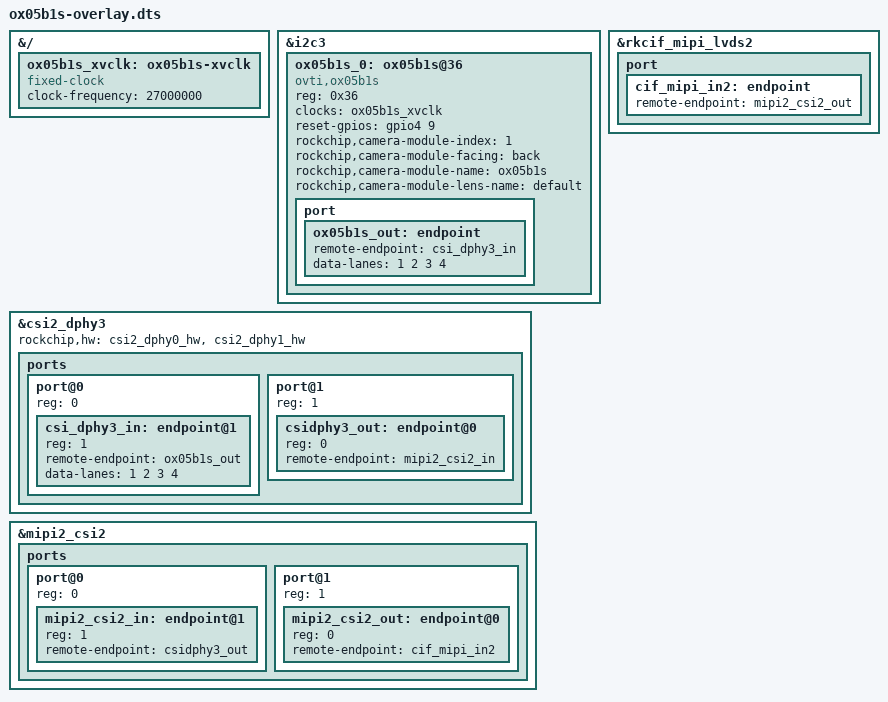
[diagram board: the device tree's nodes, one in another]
/dts-v1/;
/plugin/;

/*
 * OX05B1S on Luckfox Aura CSI1.
 * 4-lane CSI1 is csi2_dphy3 into mipi2_csi2 and rkcif_mipi_lvds2.
 * Logical dphy3 uses rockchip,hw entry 1 (index / 3), which is the
 * CSI1 analog PHY. I2C3 address 0x36. The module crystal is the clock.
 * Leave CSI1 IO0 as a GPIO input. Driving cam_clk2 stops the crystal.
 * The fixed clock below only satisfies the driver's clk_get.
 * CSI1 IO1 is GPIO4_B1 and has to sit high or the chip does not ACK.
 * Link 450 MHz is the 12 MHz table scaled onto the 27 MHz crystal.
 */

&{/} {
	ox05b1s_xvclk: ox05b1s-xvclk {
		compatible = "fixed-clock";
		#clock-cells = <0>;
		clock-frequency = <27000000>;
	};
};

&i2c3 {
	#address-cells = <1>;
	#size-cells = <0>;

	ox05b1s_0: ox05b1s@36 {
		compatible = "ovti,ox05b1s";
		reg = <0x36>;
		clocks = <&ox05b1s_xvclk>;
		clock-names = "xvclk";
		reset-gpios = <&gpio4 9 0>;
		rockchip,camera-module-index = <1>;
		rockchip,camera-module-facing = "back";
		rockchip,camera-module-name = "ox05b1s";
		rockchip,camera-module-lens-name = "default";

		port {
			ox05b1s_out: endpoint {
				remote-endpoint = <&csi_dphy3_in>;
				data-lanes = <1 2 3 4>;
			};
		};
	};
};

&csi2_dphy3 {
	status = "okay";
	rockchip,hw = <&csi2_dphy0_hw &csi2_dphy1_hw>;

	ports {
		#address-cells = <1>;
		#size-cells = <0>;

		port@0 {
			reg = <0>;
			#address-cells = <1>;
			#size-cells = <0>;

			csi_dphy3_in: endpoint@1 {
				reg = <1>;
				remote-endpoint = <&ox05b1s_out>;
				data-lanes = <1 2 3 4>;
			};
		};

		port@1 {
			reg = <1>;
			#address-cells = <1>;
			#size-cells = <0>;

			csidphy3_out: endpoint@0 {
				reg = <0>;
				remote-endpoint = <&mipi2_csi2_in>;
			};
		};
	};
};

&mipi2_csi2 {
	status = "okay";

	ports {
		#address-cells = <1>;
		#size-cells = <0>;

		port@0 {
			reg = <0>;
			#address-cells = <1>;
			#size-cells = <0>;

			mipi2_csi2_in: endpoint@1 {
				reg = <1>;
				remote-endpoint = <&csidphy3_out>;
			};
		};

		port@1 {
			reg = <1>;
			#address-cells = <1>;
			#size-cells = <0>;

			mipi2_csi2_out: endpoint@0 {
				reg = <0>;
				remote-endpoint = <&cif_mipi_in2>;
			};
		};
	};
};

&rkcif_mipi_lvds2 {
	status = "okay";

	port {
		cif_mipi_in2: endpoint {
			remote-endpoint = <&mipi2_csi2_out>;
		};
	};
};
